# N32H7xx register map
Vendor: Nationstech Ltd.; File version: 1.0
Registers are 32-bit, read-write, reset 0x0 unless marked. A register's access mark holds for its fields unless they carry their own. Offsets are from the block's base; [hi:lo] are bit positions; lines under a group give offsets from that group; {n}, {i} and the like mark numbered series; 'fields as' and 'values as' point back to an identical list.

## DSMU — Digital filter and sigma delta modulators
Base 0x400DA000
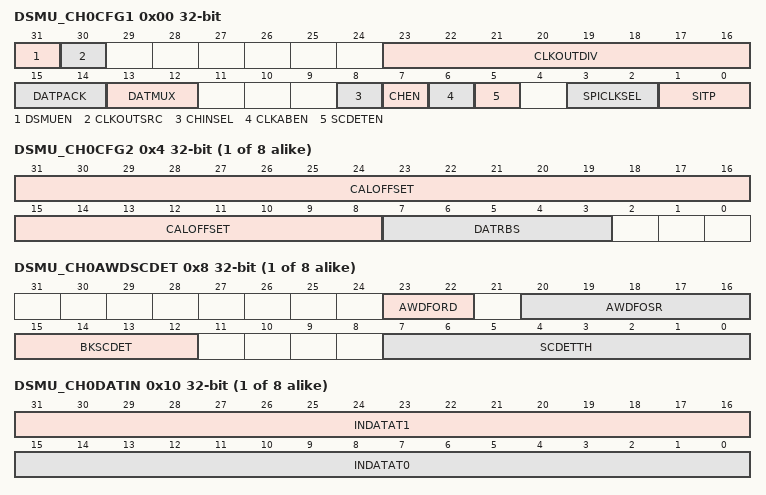
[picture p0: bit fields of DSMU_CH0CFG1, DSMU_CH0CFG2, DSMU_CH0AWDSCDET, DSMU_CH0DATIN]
0x00 DSMU_CH0CFG1 — DSMU channel 0 configure register1
  [31] DSMUEN — DSMU interface global enable
  [30] CLKOUTSRC — Output serial clock source selection
  [23:16] CLKOUTDIV — Output serial clock divider
  [15:14] DATPACK — Data packing config in input data register
  [13:12] DATMUX — Data input multiplexer for current channel
  [8] CHINSEL — Channel inputs selection
  [7] CHEN — channel enable
  [6] CLKABEN — Clock absence detector enable on current channel
  [5] SCDETEN — Short-circuit detector enable on current channel
  [3:2] SPICLKSEL — SPI clock source selection
  [1:0] SITP — Serial interface type
{0x4+0x20*i} DSMU_CH{i}CFG2 (i=0..7) — DSMU channel {i} configure register2
  [31:8] CALOFFSET — 24-bit calibration CALOFFSET value
  [7:3] DATRBS — Data right bit-shift value
{0x8+0x20*i} DSMU_CH{i}AWDSCDET (i=0..7) — DSMU channel {i} short-circuit detector and analog watchdog register
  [23:22] AWDFORD — Analog watchdog Sinc filter order on current channel
  [20:16] AWDFOSR — Analog watchdog filter oversampling ratio (decimation rate) on current channel
  [15:12] BKSCDET — Break signal assignment for short-circuit detector on current channel
  [7:0] SCDETTH — short-circuit detector threshold value for current channel
{0xC+0x20*i} DSMU_CH{i}AWDDAT ro reset 0x180 (i=0..7) — DSMU channel {i} watchdog filter data register
  [15:0] AWDDAT — Input channel watchdog data
{0x10+0x20*i} DSMU_CH{i}DATIN (i=0..7) — DSMU channel {i} input data register
  [31:16] INDATAT1 — Input data for current channel or following channel
  [15:0] INDATAT0 — Input data for current channel
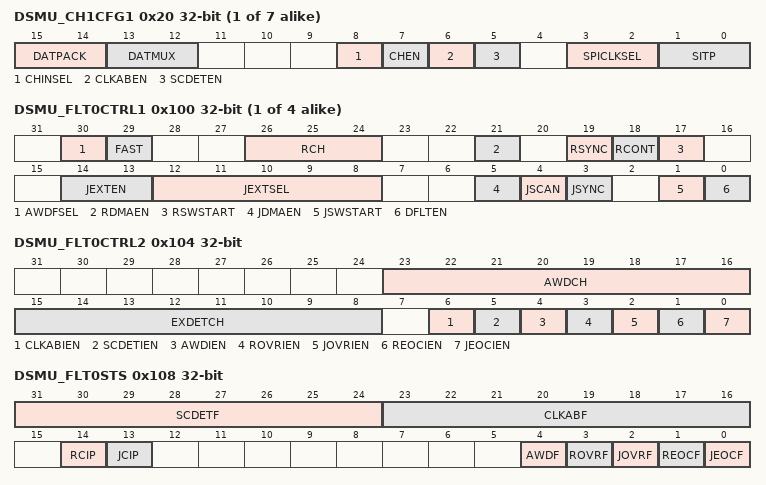
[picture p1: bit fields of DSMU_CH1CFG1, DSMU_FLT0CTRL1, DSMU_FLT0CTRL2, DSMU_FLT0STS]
{0x0+0x20*i} DSMU_CH{i}CFG1 (i=1..7) — DSMU channel {i} configure register1
  [15:14] DATPACK — Data packing config in input data register
  [13:12] DATMUX — Data input multiplexer for current channel
  [8] CHINSEL — Channel inputs selection
  [7] CHEN — channel enable
  [6] CLKABEN — Clock absence detector enable on current channel
  [5] SCDETEN — Short-circuit detector enable on current channel
  [3:2] SPICLKSEL — SPI clock source selection
  [1:0] SITP — Serial interface type
{0x100+0x80*i} DSMU_FLT{i}CTRL1 (i=0..3) — DSMU filter {i} control register 1
  [30] AWDFSEL — Analog watchdog input data selection
  [29] FAST — Fast conversion mode selection for regular conversions
  [26:24] RCH — Regular conversion channel
  [21] RDMAEN — DMA channel enabled to read regular conversion data
  [19] RSYNC — Launch regular conversion synchronously with DSMU_FLT0
  [18] RCONT — Continuous mode config for regular conversions
  [17] RSWSTART — Software trigger of a conversion on the regular channel
  [14:13] JEXTEN — External trigger enable and trigger active edge selection for injected conversions
  [12:8] JEXTSEL — External trigger signal selection for launching injected conversions
  [5] JDMAEN — DMA channel enabled to read data for the injected conversion
  [4] JSCAN — Injected scanning conversion mode
  [3] JSYNC — Launch an injected conversion synchronously with the DSMU_FLT0 JSWSTART event
  [1] JSWSTART — Start a conversion of the injected group of channels
  [0] DFLTEN — DSMU filter enable
0x104 DSMU_FLT0CTRL2 — DSMU filter 0 control register 2
  [23:16] AWDCH — AWDAnalog watchdog channel selection
  [15:8] EXDETCH — Extremes detector channel selection
  [6] CLKABIEN — Clock absence interrupt enable
  [5] SCDETIEN — Short-circuit detector interrupt enable
  [4] AWDIEN — Analog watchdog interrupt enable
  [3] ROVRIEN — Regular data overrun interrupt enable
  [2] JOVRIEN — Injected data overrun interrupt enable
  [1] REOCIEN — Regular conversion end interrupt enable
  [0] JEOCIEN — Injected conversion end interrupt enable
0x108 DSMU_FLT0STS ro — DSMU filter 0 status register
  [31:24] SCDETF — short-circuit event flag
  [23:16] CLKABF — Clock absence event flag
  [14] RCIP — Regular conversion active status
  [13] JCIP — Injected conversion active status
  [4] AWDF — Analog watchdog event flag
  [3] ROVRF — Regular conversion overrun flag
  [2] JOVRF — Injected conversion overrun flag
  [1] REOCF — Regular conversion end event flag
  [0] JEOCF — Injected conversion end event flag
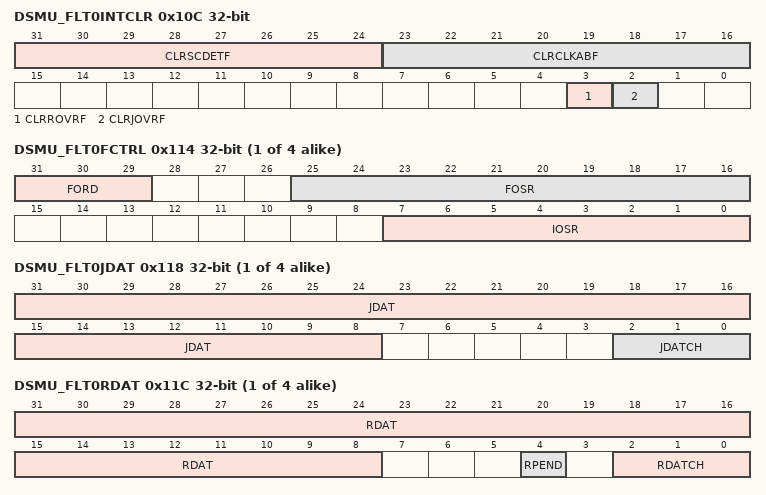
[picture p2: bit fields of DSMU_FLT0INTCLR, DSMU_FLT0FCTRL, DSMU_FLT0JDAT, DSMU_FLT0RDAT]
0x10C DSMU_FLT0INTCLR wo — DSMU filter 0 interrupt flag clear register
  [31:24] CLRSCDETF — Clear the short-circuit event flag
  [23:16] CLRCLKABF — Clear the clock absence flag
  [3] CLRROVRF — Clear the regular conversion overrun flag
  [2] CLRJOVRF — Clear the injected conversion overrun flag
{0x110+0x80*i} DSMU_FLT{i}JCHG (i=0..3) — DSMU filter {i} injected channel group selection register
  [7:0] JCHG — Injected channel group selection
{0x114+0x80*i} DSMU_FLT{i}FCTRL (i=0..3) — DSMU filter {i} function control register
  [31:29] FORD — Sinc filter order
  [25:16] FOSR — Sinc filter oversampling ratio (decimation rate)
  [7:0] IOSR — Integrator oversampling ratio (averaging length)
{0x118+0x80*i} DSMU_FLT{i}JDAT ro (i=0..3) — DSMU filter {i} injected conversion data register
  [31:8] JDAT — Injected group conversion data
  [2:0] JDATCH — Injected channel most recently converted
{0x11C+0x80*i} DSMU_FLT{i}RDAT ro (i=0..3) — DSMU filter {i} data register for the regular channel
  [31:8] RDAT — Regular channel conversion data
  [4] RPEND — Regular channel pending data
  [2:0] RDATCH — Regular channel most recently converted
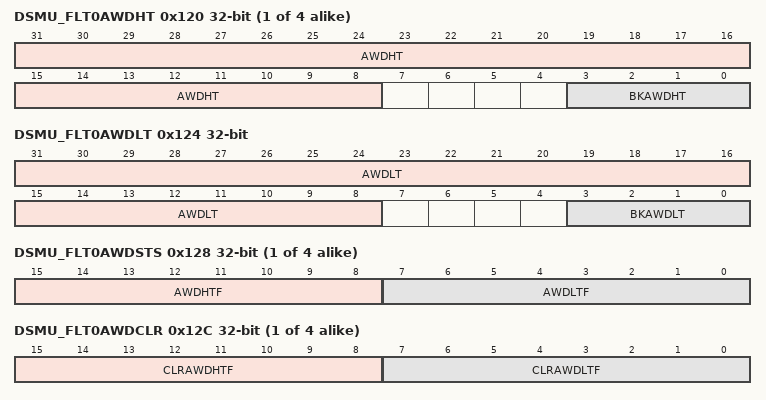
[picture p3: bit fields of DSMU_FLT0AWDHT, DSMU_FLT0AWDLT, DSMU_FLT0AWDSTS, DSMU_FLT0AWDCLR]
{0x120+0x80*i} DSMU_FLT{i}AWDHT (i=0..3) — DSMU filter {i} analog watchdog high threshold register
  [31:8] AWDHT — Analog watchdog threshold high
  [3:0] BKAWDHT — Break signal assignment to analog watchdog threshold high event
0x124 DSMU_FLT0AWDLT — DSMU filter 0 analog watchdog low threshold register
  [31:8] AWDLT — Analog watchdog threshold low
  [3:0] BKAWDLT — Break signal assignment to analog watchdog threshold low event
{0x128+0x80*i} DSMU_FLT{i}AWDSTS ro (i=0..3) — DSMU filter {i} analog watchdog status register
  [15:8] AWDHTF — Analog watchdog threshold high flag
  [7:0] AWDLTF — Analog watchdog threshold low flag
{0x12C+0x80*i} DSMU_FLT{i}AWDCLR wo (i=0..3) — DSMU filter {i} analog watchdog clear flag register
  [15:8] CLRAWDHTF — Clear the analog watchdog threshold high flag
  [7:0] CLRAWDLTF — Clear the analog watchdog threshold low flag
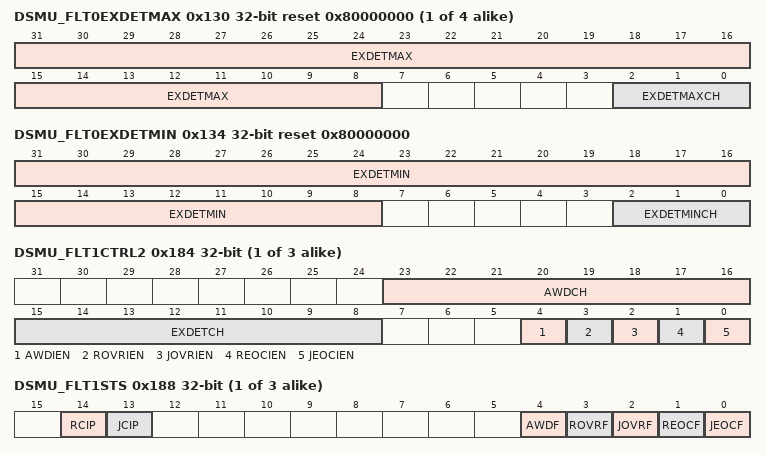
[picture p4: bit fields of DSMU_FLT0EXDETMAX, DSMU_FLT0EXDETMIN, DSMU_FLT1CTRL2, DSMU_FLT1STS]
{0x130+0x80*i} DSMU_FLT{i}EXDETMAX ro reset 0x80000000 (i=0..3) — DSMU filter {i} extremes detector maximum register
  [31:8] EXDETMAX — Extremes detector maximum value
  [2:0] EXDETMAXCH — Extremes detector maximum data channel
0x134 DSMU_FLT0EXDETMIN ro reset 0x80000000 — DSMU filter 0 extremes detector minimum register
  [31:8] EXDETMIN — Extremes detector minimum value
  [2:0] EXDETMINCH — Extremes detector minimum data channel
{0x138+0x80*i} DSMU_FLT{i}COVTIM ro (i=0..3) — DSMU filter {i} conversion timer register
  [31:4] COVCNT — 28-bit timer counting conversion time
{0x104+0x80*i} DSMU_FLT{i}CTRL2 (i=1..3) — DSMU filter {i} control register 2
  [23:16] AWDCH — AWDAnalog watchdog channel selection
  [15:8] EXDETCH — Extremes detector channel selection
  [4] AWDIEN — Analog watchdog interrupt enable
  [3] ROVRIEN — Regular data overrun interrupt enable
  [2] JOVRIEN — Injected data overrun interrupt enable
  [1] REOCIEN — Regular conversion end interrupt enable
  [0] JEOCIEN — Injected conversion end interrupt enable
{0x108+0x80*i} DSMU_FLT{i}STS ro (i=1..3) — DSMU filter {i} status register
  [14] RCIP — Regular conversion active status
  [13] JCIP — Injected conversion active status
  [4] AWDF — Analog watchdog event flag
  [3] ROVRF — Regular conversion overrun flag
  [2] JOVRF — Injected conversion overrun flag
  [1] REOCF — Regular conversion end event flag
  [0] JEOCF — Injected conversion end event flag
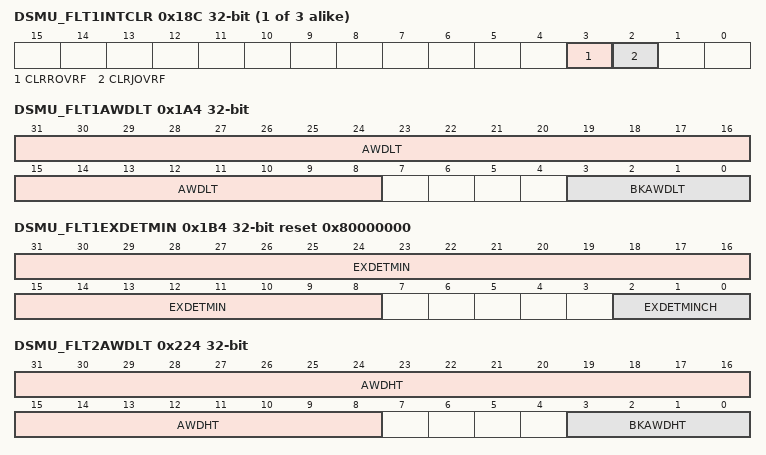
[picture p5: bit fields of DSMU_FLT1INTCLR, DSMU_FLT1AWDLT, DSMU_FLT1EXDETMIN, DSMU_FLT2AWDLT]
{0x10C+0x80*i} DSMU_FLT{i}INTCLR wo (i=1..3) — DSMU filter {i} interrupt flag clear register
  [3] CLRROVRF — Clear the regular conversion overrun flag
  [2] CLRJOVRF — Clear the injected conversion overrun flag
0x1A4 DSMU_FLT1AWDLT — DSMU filter 1 analog watchdog low threshold register
  fields as DSMU_FLT0AWDLT
0x1B4 DSMU_FLT1EXDETMIN ro reset 0x80000000 — DSMU filter 1 extremes detector minimum register
  fields as DSMU_FLT0EXDETMIN
0x224 DSMU_FLT2AWDLT — DSMU filter 2 analog watchdog low threshold register
  fields as DSMU_FLT0AWDHT
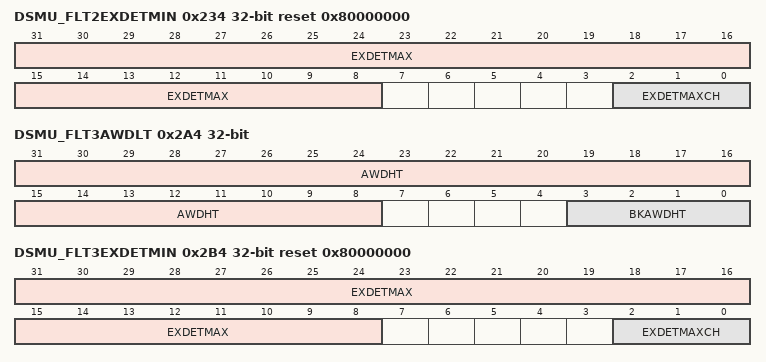
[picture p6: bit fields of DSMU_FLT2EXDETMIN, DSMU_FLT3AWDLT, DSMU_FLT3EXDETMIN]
0x234 DSMU_FLT2EXDETMIN ro reset 0x80000000 — DSMU filter 2 extremes detector minimum register
  fields as DSMU_FLT0EXDETMAX
0x2A4 DSMU_FLT3AWDLT — DSMU filter 3 analog watchdog low threshold register
  fields as DSMU_FLT0AWDHT
0x2B4 DSMU_FLT3EXDETMIN ro reset 0x80000000 — DSMU filter 3 extremes detector minimum register
  fields as DSMU_FLT0EXDETMAX
